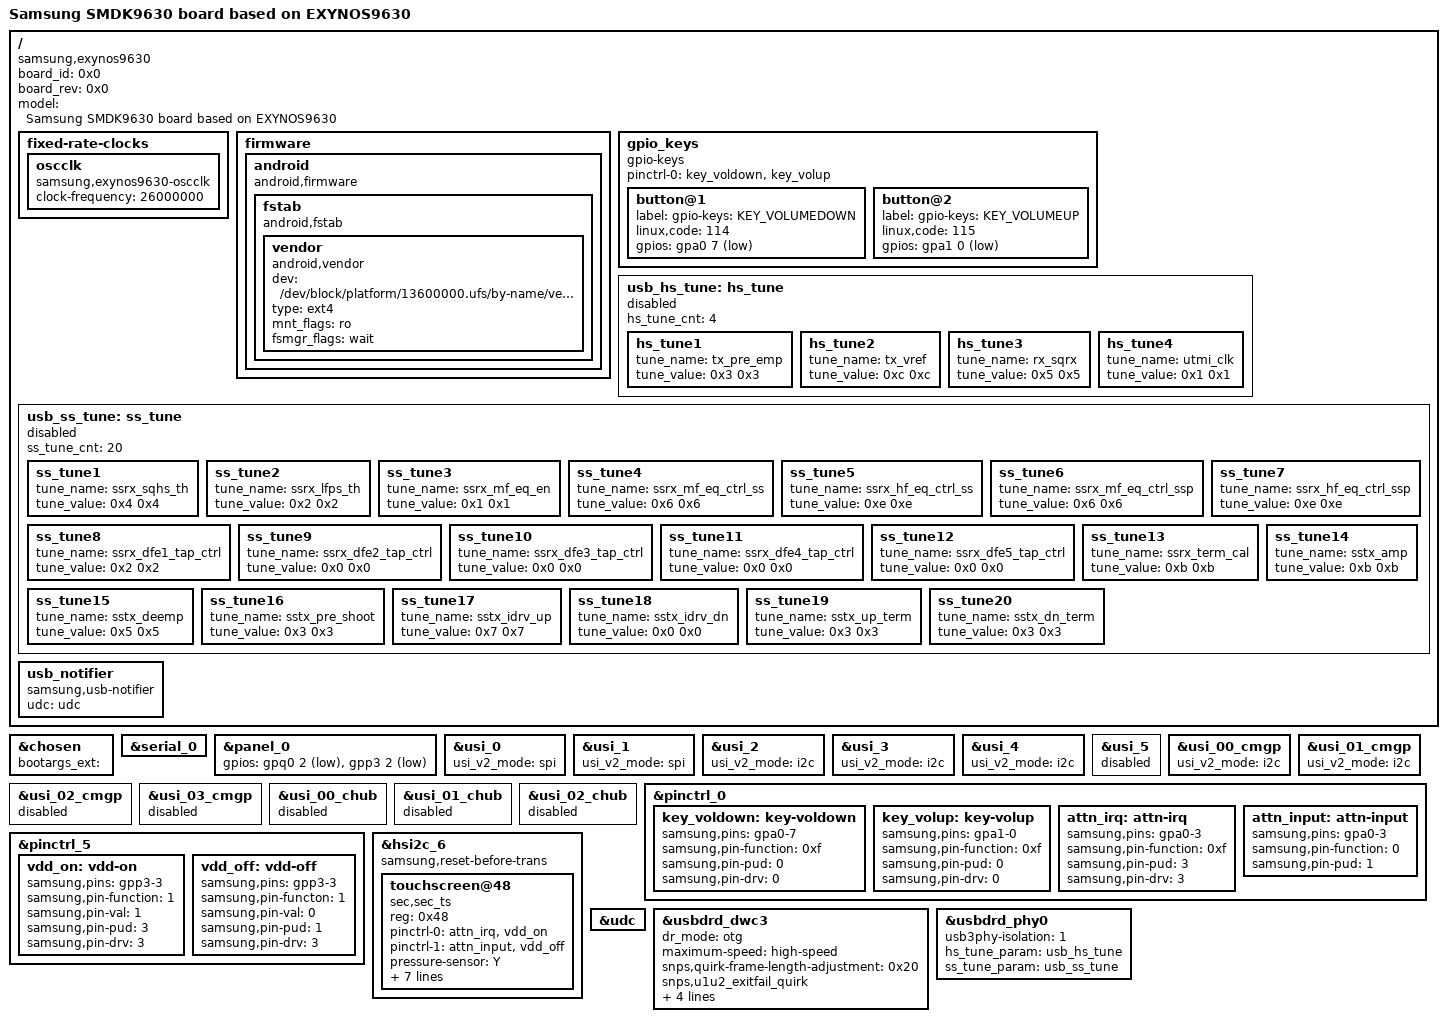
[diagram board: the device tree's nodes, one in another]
/*
 * SAMSUNG EXYNOS9630 board device tree source
 *
 * Copyright (c) 2019 Samsung Electronics Co., Ltd.
 *		http://www.samsung.com
 *
 * This program is free software; you can redistribute it and/or modify
 * it under the terms of the GNU General Public License version 2 as
 * published by the Free Software Foundation.
 */

/dts-v1/;
/plugin/;

/ {
	compatible = "samsung,exynos9630", "samsung,SMDK9630";
	board_id = <0x0>;
	board_rev = <0x0>;

	fragment@model {
		target-path = "/";
		__overlay__ {
			#address-cells = <2>;
			#size-cells = <1>;

			model = "Samsung SMDK9630 board based on EXYNOS9630";

			fixed-rate-clocks {
				oscclk {
					compatible = "samsung,exynos9630-oscclk";
					clock-frequency = <26000000>;
				};
			};

			firmware {
				android {
					compatible = "android,firmware";
/*
					vbmeta {
						compatible = "android,vbmeta";
						parts = "vbmeta,boot,system,vendor,dtbo";
					};
*/
					fstab {
						compatible = "android,fstab";
						vendor {
							compatible = "android,vendor";
							dev = "/dev/block/platform/13600000.ufs/by-name/vendor";
							type = "ext4";
							mnt_flags = "ro";
							fsmgr_flags = "wait";
/*
							fsmgr_flags = "wait,avb";
*/
						};
					};
				};
			};

			gpio_keys {
				status = "okay";
				compatible = "gpio-keys";
				pinctrl-names = "default";
				pinctrl-0 = <&key_voldown &key_volup>;

				button@1 {
					label = "gpio-keys: KEY_VOLUMEDOWN";
					linux,code = <114>;
					gpios = <&gpa0 7 0xf>;
				};
				button@2 {
					label = "gpio-keys: KEY_VOLUMEUP";
					linux,code = <115>;
					gpios = <&gpa1 0 0xf>;
				};
			};

			usb_hs_tune:hs_tune {
				status = "disabled";
				hs_tune_cnt = <4>;
				/* value = <device host> */
				hs_tune1 {
					tune_name = "tx_pre_emp";
					tune_value = <0x3 0x3>;
				};

				hs_tune2 {
					tune_name = "tx_vref";
					tune_value = <0xc 0xc>;
				};

				hs_tune3 {
					tune_name = "rx_sqrx";
					tune_value = <0x5 0x5>;
				};

				hs_tune4 {
					tune_name = "utmi_clk";
					tune_value = <0x1 0x1>;
				};
			};

			usb_ss_tune:ss_tune {
				status = "disabled";
				ss_tune_cnt = <20>;
				/* value = <device host> */
				ss_tune1 {
					tune_name = "ssrx_sqhs_th";
					tune_value = <0x4 0x4>;
				};

				ss_tune2 {
					tune_name = "ssrx_lfps_th";
					tune_value = <0x2 0x2>;
				};

				ss_tune3 {
					tune_name = "ssrx_mf_eq_en";
					tune_value = <0x1 0x1>;
				};

				ss_tune4 {
					tune_name = "ssrx_mf_eq_ctrl_ss";
					tune_value = <0x6 0x6>;
				};

				ss_tune5 {
					tune_name = "ssrx_hf_eq_ctrl_ss";
					tune_value = <0xe 0xe>;
				};

				ss_tune6 {
					tune_name = "ssrx_mf_eq_ctrl_ssp";
					tune_value = <0x6 0x6>;
				};

				ss_tune7 {
					tune_name = "ssrx_hf_eq_ctrl_ssp";
					tune_value = <0xe 0xe>;
				};

				ss_tune8 {
					tune_name = "ssrx_dfe1_tap_ctrl";
					tune_value = <0x2 0x2>;
				};

				ss_tune9 {
					tune_name = "ssrx_dfe2_tap_ctrl";
					tune_value = <0x0 0x0>;
				};

				ss_tune10 {
					tune_name = "ssrx_dfe3_tap_ctrl";
					tune_value = <0x0 0x0>;
				};

				ss_tune11 {
					tune_name = "ssrx_dfe4_tap_ctrl";
					tune_value = <0x0 0x0>;
				};

				ss_tune12 {
					tune_name = "ssrx_dfe5_tap_ctrl";
					tune_value = <0x0 0x0>;
				};

				ss_tune13 {
					tune_name = "ssrx_term_cal";
					tune_value = <0xb 0xb>;
				};

				ss_tune14 {
					tune_name = "sstx_amp";
					tune_value = <0xb 0xb>;
				};

				ss_tune15 {
					tune_name = "sstx_deemp";
					tune_value = <0x5 0x5>;
				};

				ss_tune16 {
					tune_name = "sstx_pre_shoot";
					tune_value = <0x3 0x3>;
				};

				ss_tune17 {
					tune_name = "sstx_idrv_up";
					tune_value = <0x7 0x7>;
				};

				ss_tune18 {
					tune_name = "sstx_idrv_dn";
					tune_value = <0x0 0x0>;
				};

				ss_tune19 {
					tune_name = "sstx_up_term";
					tune_value = <0x3 0x3>;
				};

				ss_tune20 {
					tune_name = "sstx_dn_term";
					tune_value = <0x3 0x3>;
				};
			};

			usb_notifier {
				compatible = "samsung,usb-notifier";
				udc = <&udc>;
			};

		}; /* end of __overlay__ */
	}; /* end of fragment */
}; /* end of root */

&chosen {
	bootargs_ext = "";
};

&serial_0 {
	status = "okay";
};

&panel_0 {
	/* reset, power */
	gpios = <&gpq0 2 0x1>, <&gpp3 2 0x1>;
};

/* USI_00 */
&usi_0 {
	usi_v2_mode = "spi";
	status = "okay";
};

/* USI_01 */
&usi_1 {
	usi_v2_mode = "spi";
	status = "okay";
};

/* USI_02 */
&usi_2 {
	usi_v2_mode = "i2c";
	status = "okay";
};

/* USI_03 */
&usi_3 {
	usi_v2_mode = "i2c";
	status = "okay";
};

/* USI_04 */
&usi_4 {
	usi_v2_mode = "i2c";
	status = "okay";
};

/* USI_05 */
&usi_5 {
	/*	usi_v2_mode = "i2c" or "spi" or "uart"	*/
	status = "disabled";
};

/* USI_00_CMGP */
&usi_00_cmgp {
	usi_v2_mode = "i2c";
	status = "okay";
};

/* USI_01_CMGP */
&usi_01_cmgp {
	usi_v2_mode = "i2c";
	status = "okay";
};

/* USI_02_CMGP */
&usi_02_cmgp {
	/*	usi_v2_mode = "i2c" or "spi" or "uart"	*/
	status = "disabled";
};

/* USI_03_CMGP */
&usi_03_cmgp {
	/*	usi_v2_mode = "i2c" or "spi" or "uart"	*/
	status = "disabled";
};

/* USI_00_CHUB */
&usi_00_chub {
	/*	usi_v2_mode = "i2c" or "spi" or "uart"	*/
	status = "disabled";
};

/* USI_01_CHUB */
&usi_01_chub {
	/*	usi_v2_mode = "i2c" or "spi" or "uart"	*/
	status = "disabled";
};

/* USI_02_CHUB */
&usi_02_chub {
	/*	usi_v2_mode = "i2c" or "spi" or "uart"	*/
	status = "disabled";
};

&pinctrl_0 {
	key_voldown: key-voldown {
		samsung,pins = "gpa0-7";
		samsung,pin-function = <0xf>;
		samsung,pin-pud = <0>;
		samsung,pin-drv = <0>;
	};

	key_volup: key-volup {
		samsung,pins = "gpa1-0";
		samsung,pin-function = <0xf>;
		samsung,pin-pud = <0>;
		samsung,pin-drv = <0>;
	};

	attn_irq: attn-irq {
		samsung,pins = "gpa0-3";
		samsung,pin-function = <0xf>;
		samsung,pin-pud = <3>;
		samsung,pin-drv = <3>;
	};

	attn_input: attn-input {
		samsung,pins = "gpa0-3";
		samsung,pin-function = <0>;
		samsung,pin-pud = <1>;
	};
};

&pinctrl_5 {
	vdd_on: vdd-on {
		samsung,pins = "gpp3-3";
		samsung,pin-function = <1>;
		samsung,pin-val = <1>;
		samsung,pin-pud = <3>;
		samsung,pin-drv = <3>;
	};

	vdd_off: vdd-off {
		samsung,pins = "gpp3-3";
		samsung,pin-functon = <1>;
		samsung,pin-val = <0>;
		samsung,pin-pud = <1>;
		samsung,pin-drv = <3>;
	};
};

&hsi2c_6 {
	#address-cells = <1>;
	#size-cells = <0>;
	status = "okay";
	samsung,reset-before-trans;
	touchscreen@48 {
		compatible = "sec,sec_ts";
		reg = <0x48>;
		pinctrl-names = "on_state", "off_state";
		pinctrl-0 = <&attn_irq &vdd_on>;
		pinctrl-1 = <&attn_input &vdd_off>;
		pressure-sensor = "Y";
		sec,irq_gpio = <&gpa0 3 0>;
		sec,irq_type = <8200>;
		sec,max_coords = <4095 4095>;
		sec,mis_cal_check = <1>;
//		sec,regulator_avdd = "";
//		sec,regulator_boot_on;
//		sec,always_lpmode = <1>;
		sec,project_name = "neus";
		sec,firmware_name = "tsp_sec/y761_dream1.fw", "tsp_sec/y761_dream1.fw";
	};
};

&udc {
	status = "okay";
};

&usbdrd_dwc3 {
	dr_mode = "otg";
	maximum-speed = "high-speed";
	snps,quirk-frame-length-adjustment = <0x20>;
	snps,u1u2_exitfail_quirk;
	/* ux_exit_in_px should be defined in MK, LT */
	snps,ux_exit_in_px_quirk;
	/* elastic_buf_mode_quirk should be defined in MK */
	snps,elastic_buf_mode_quirk;
	/* usb3-lpm-capable;
	snps,usb3_lpm_capable; 
	adj-sof-accuracy = <1>; */
	/*
	 * dis-u2-freeclk-exists-quirk, dis_u2_susphy_quirk are alternative.
	 * One of them should be selected
	 */
	snps,dis-u2-freeclk-exists-quirk;
	/*snps,dis_u2_susphy_quirk;*/

	usb_audio_offloading = <0>;
//	abox = <&abox>; /* Temporary block */
};

&usbdrd_phy0 {
	status = "okay";
	
	usb3phy-isolation= <1>;
	pinctrl-names = "default";
//	pinctrl-0 = <&phy_port>;
//	phy,gpio_phy_port = <&gpg0 4 0x0>;
	hs_tune_param = <&usb_hs_tune>;
	ss_tune_param = <&usb_ss_tune>;
};

